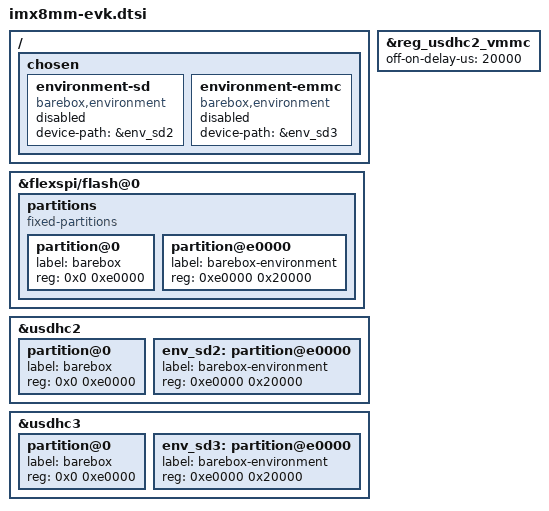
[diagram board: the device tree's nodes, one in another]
// SPDX-License-Identifier: (GPL-2.0 OR MIT)
/*
 * Copyright 2017 NXP
 * Copyright (C) 2017 Pengutronix, Lucas Stach <kernel@pengutronix.de>
 */

/ {
	chosen {
		environment-sd {
			compatible = "barebox,environment";
			device-path = &env_sd2;
			status = "disabled";
		};
		environment-emmc {
			compatible = "barebox,environment";
			device-path = &env_sd3;
			status = "disabled";
		};
	};
};

&{flexspi/flash@0} {
	partitions {
		compatible = "fixed-partitions";
		#address-cells = <1>;
		#size-cells = <1>;

		partition@0 {
			label = "barebox";
			reg = <0x0 0xe0000>;
		};

		partition@e0000 {
			label = "barebox-environment";
			reg = <0xe0000 0x20000>;
		};
	};

};

&reg_usdhc2_vmmc {
	off-on-delay-us = <20000>;
};

&usdhc2 {
	#address-cells = <1>;
	#size-cells = <1>;

	partition@0 {
		label = "barebox";
		reg = <0x0 0xe0000>;
	};

	env_sd2: partition@e0000 {
		label = "barebox-environment";
		reg = <0xe0000 0x20000>;
	};
};

&usdhc3 {
	#address-cells = <1>;
	#size-cells = <1>;

	partition@0 {
		label = "barebox";
		reg = <0x0 0xe0000>;
	};

	env_sd3: partition@e0000 {
		label = "barebox-environment";
		reg = <0xe0000 0x20000>;
	};
};
